# K1921VK028 register map
Vendor: NIIET; Series: K1921VKx; File version: 2.17
CPU: CM4 r0p1, little endian, MPU, FPU, 4 interrupt priority bits
Registers are 32-bit, read-write, reset 0x0 unless marked. A register's access mark holds for its fields unless they carry their own. Offsets are from the block's base; [hi:lo] are bit positions; {n}, {i} and the like mark numbered series.

## PMU — Power management unit registers
Base 0x40082000
0x00 CFG — PMU Configuration Register
  [0] EN — Enable PMU
0x04 PUDEL — PMU Powerup Delay Value
  [15:0] VAL — Delay value for powerup peripheral blocks (in REFCLK ticks)
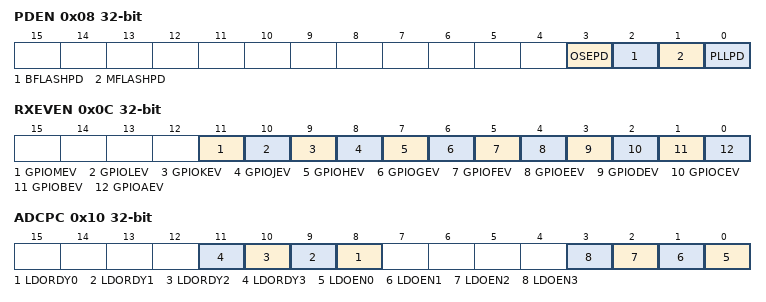
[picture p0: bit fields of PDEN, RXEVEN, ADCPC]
0x08 PDEN — PMU Enable Powerdown for peripheral
  [3] OSEPD — Enable powerdown for external oscillator
  [2] BFLASHPD — Enable powerdown for BFLASH
  [1] MFLASHPD — Enable powerdown for MFLASH
  [0] PLLPD — Enable powerdown for PLL
0x0C RXEVEN — PMU RX Event generation enable register
  [11] GPIOMEV — Enable RX event from GPIOM pins
  [10] GPIOLEV — Enable RX event from GPIOL pins
  [9] GPIOKEV — Enable RX event from GPIOK pins
  [8] GPIOJEV — Enable RX event from GPIOJ pins
  [7] GPIOHEV — Enable RX event from GPIOH pins
  [6] GPIOGEV — Enable RX event from GPIOG pins
  [5] GPIOFEV — Enable RX event from GPIOF pins
  [4] GPIOEEV — Enable RX event from GPIOE pins
  [3] GPIODEV — Enable RX event from GPIOD pins
  [2] GPIOCEV — Enable RX event from GPIOC pins
  [1] GPIOBEV — Enable RX event from GPIOB pins
  [0] GPIOAEV — Enable RX event from GPIOA pins
0x10 ADCPC — ADC Power Control
  [n+8] LDORDY{n} ro (n=0..3) — ADC{n} LDO ready status
  [n] LDOEN{n} (n=0..3) — Enable LDO of ADC{n}

## WDT — Watchdog control registers
Base 0x40083000
0x00 LOAD — Watchdog Load Register
  [31:0] VAL
0x04 VALUE ro — Watchdog Value Register
  [31:0] VAL
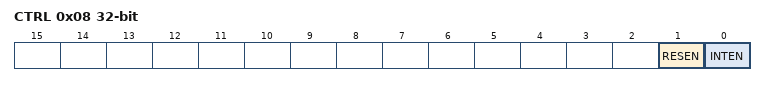
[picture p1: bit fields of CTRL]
0x08 CTRL — Watchdog Control Register
  [1] RESEN — Enable watchdog reset output
  [0] INTEN — Enable the interrupt event
0x0C INTCLR wo — Watchdog Clear Interrupt Register
  [31:0] WDTCLR
0x10 RIS ro — Watchdog Raw Interrupt Status Register
  [0] RAWWDTINT — Raw interrupt status from the counter
0x14 MIS ro — Watchdog Interrupt Status Register
  [0] WDTINT — Enabled interrupt status from the counter
0xC00 LOCK wo — Watchdog Lock Register
  [0] REGWRDIS — Disable write to all registers Watchdog

## TMR0 — TMR controller registers
Base 0x40091000
Same registers: TMR1 0x40092000, TMR2 0x40093000, TMR3 0x40094000
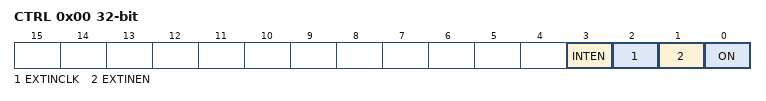
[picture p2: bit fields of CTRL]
0x00 CTRL — Control Timer register
  [3] INTEN — Enable Timer interrupt
  [2] EXTINCLK — Enable external input as CLK
  [1] EXTINEN — Enable external input as ENABLE
  [0] ON — Enable Timer
0x04 VALUE — Current value timer register
  [31:0] VAL
0x08 LOAD — Reload value timer register
  [31:0] VAL
0x0C INTSTATUS — Interrupt status register
  [0] INT — Timer interrupt flag
0x10 DMAREQ — DMA request register
  [0] EN
0x14 ADCSOC — ADC start of conversion register
  [0] EN

## ETMR0 — ETMR controller registers
Base 0x40095000
Same registers: ETMR1 0x40096000, ETMR2 0x40097000, ETMR3 0x40098000
0x00 LOAD
  [31:0] VAL
0x04 VALUE ro — Current value timer register
  [31:0] VAL
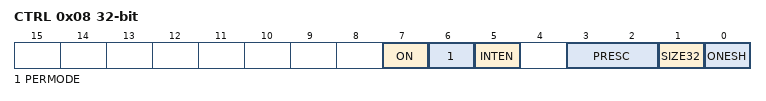
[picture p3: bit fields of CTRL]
0x08 CTRL — Timer control register
  [7] ON — Enable timer
  [6] PERMODE — Select timer mode: free-run or periodic
    0=FreeRun (free timer count); 1=PeriodicRun (periodic timer count)
  [5] INTEN — Interrupt enable
  [3:2] PRESC — Precaler select
    0=Div1 (PCLK/1 clock); 1=Div16 (PCLK/16 clock); 2=Div256 (PCLK/256 clock)
  [1] SIZE32 — Select size if counter: 16 or 32 bit
    0=16 bit counter; 1=32bit counter
  [0] ONESH — One-shot count
0x0C INTCLR wo — Interrupt clear register
  [0] INTCLR — Clear timer interrupt
0x10 RIS ro — Raw interrupt status register
  [0] RINT — Raw interrupt status flag
0x14 MIS ro — Interrupt status register
  [0] INT — Timer interrupt flag
0x18 BGLOAD — Background load register
  [31:0] VAL
0x1C DMAREQ — DMA request register
  [0] EN

## TMU — TMU controller registers
Base 0x40040000
0x00 XIN — X input register
  [31:0] VAL
0x04 YIN — Y input register
  [31:0] VAL
0x08 PHIN — Phase input register
  [31:0] VAL
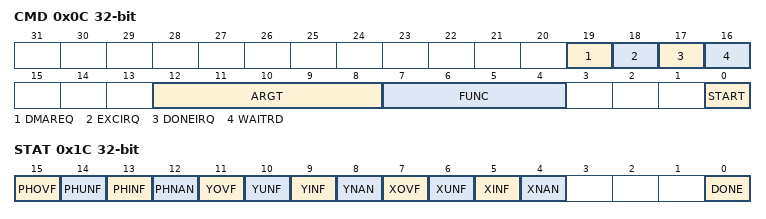
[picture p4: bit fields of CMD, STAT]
0x0C CMD — Command register
  [19] DMAREQ — Generate DMA request when calculation done
  [18] EXCIRQ — Generate interrupt when any exception happend
  [17] DONEIRQ — Generate interrupt when calculation done
  [16] WAITRD — Wait calculation complete when any output register read
  [12:8] ARGT — Input and output argument type: 0-Q28, 1-Q27, . . ., 20-Q8, 31-FP
  [7:4] FUNC — Select function to compute
    0=SinCos (sine and cosine functions); 1=Rect2Pol (rectangular to polar coordinates); 2=Pol2Rect (polar to rectangular coordinates); 3=Rot (Vector rotation)
  [0] START wo — Start calculations
0x10 XOUT — X output register
  [31:0] VAL
0x14 YOUT — Y output register
  [31:0] VAL
0x18 PHOUT — Phase output register
  [31:0] VAL
0x1C STAT — Status register
  [15] PHOVF ro — PHIN value is bigger than max alowed number exception status
  [14] PHUNF ro — PHIN value is few than min alowed number exception status
  [13] PHINF ro — PHIN value is INF exception status
  [12] PHNAN ro — PHIN value is NaN exception status
  [11] YOVF ro — YIN value is bigger than max alowed number exception status
  [10] YUNF ro — YIN value is few than min alowed number exception status
  [9] YINF ro — YIN value is INF exception status
  [8] YNAN ro — YIN value is NaN exception status
  [7] XOVF ro — XIN value is bigger than max alowed number exception status
  [6] XUNF ro — XIN value is few than min alowed number exception status
  [5] XINF ro — XIN value is INF exception status
  [4] XNAN ro — XIN value is NaN exception status
  [0] DONE — Calculation done status
